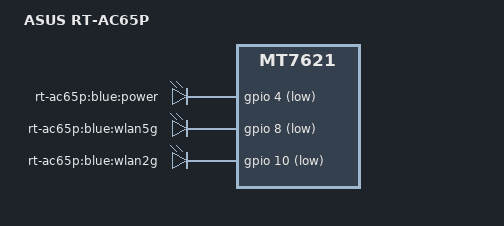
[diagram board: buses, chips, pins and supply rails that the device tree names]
// SPDX-License-Identifier: GPL-2.0-or-later OR MIT

#include "mt7621_asus_rt-acx5p.dtsi"

/ {
	compatible = "asus,rt-ac65p", "mediatek,mt7621-soc";
	model = "ASUS RT-AC65P";

	aliases {
		led-boot = &led_power;
		led-failsafe = &led_power;
		led-running = &led_power;
		led-upgrade = &led_power;
	};

	leds {
		compatible = "gpio-leds";

		led_power: power {
			label = "rt-ac65p:blue:power";
			gpios = <&gpio 4 GPIO_ACTIVE_LOW>;
		};

		wlan5g {
			label = "rt-ac65p:blue:wlan5g";
			gpios = <&gpio 8 GPIO_ACTIVE_LOW>;
			linux,default-trigger = "phy1radio";
		};

		wlan2g {
			label = "rt-ac65p:blue:wlan2g";
			gpios = <&gpio 10 GPIO_ACTIVE_LOW>;
			linux,default-trigger = "phy0radio";
		};
	};
};
